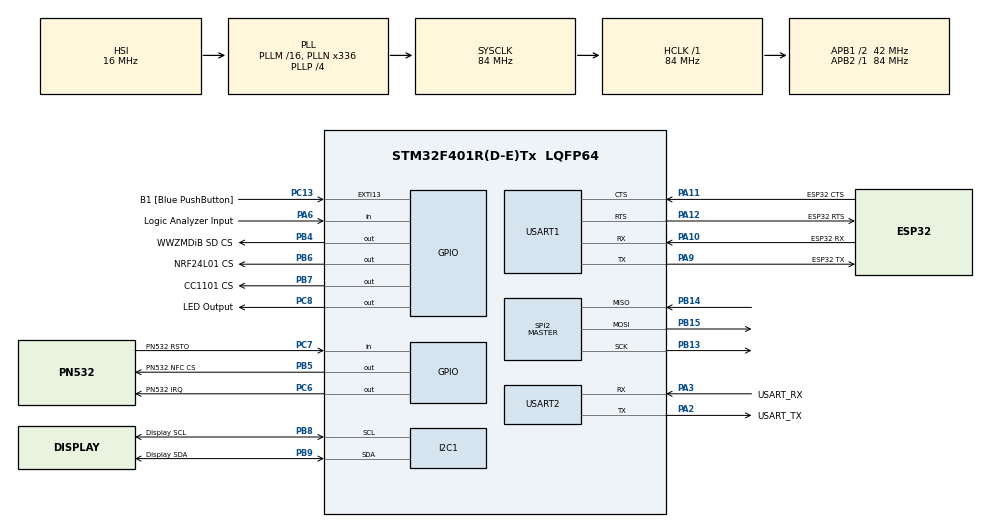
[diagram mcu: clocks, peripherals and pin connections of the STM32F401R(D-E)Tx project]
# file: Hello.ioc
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Dma.Request0=TIM3_CH4/UP
Dma.TIM3_CH4/UP.0.Direction=DMA_PERIPH_TO_MEMORY
Dma.TIM3_CH4/UP.0.FIFOMode=DMA_FIFOMODE_DISABLE
Dma.TIM3_CH4/UP.0.Instance=DMA1_Stream2
Dma.TIM3_CH4/UP.0.MemDataAlignment=DMA_MDATAALIGN_HALFWORD
Dma.TIM3_CH4/UP.0.MemInc=DMA_MINC_ENABLE
Dma.TIM3_CH4/UP.0.Mode=DMA_CIRCULAR
Dma.TIM3_CH4/UP.0.PeriphDataAlignment=DMA_PDATAALIGN_HALFWORD
Dma.TIM3_CH4/UP.0.PeriphInc=DMA_PINC_DISABLE
Dma.TIM3_CH4/UP.0.Priority=DMA_PRIORITY_HIGH
FREERTOS.Tasks01=defaultTask,24,128,StartDefaultTask,Default,NULL,Dynamic,NULL,NULL
Mcu.Family=STM32F4
Mcu.Name=STM32F401R(D-E)Tx
Mcu.Package=LQFP64
NVIC.DMA1_Stream2_IRQn=true\:5\:0\:false\:false\:true\:true\:false\:true\:true
NVIC.PriorityGroup=NVIC_PRIORITYGROUP_4
NVIC.TIM1_UP_TIM10_IRQn=true\:15\:0\:false\:false\:true\:false\:false\:true\:true
NVIC.TimeBase=TIM1_UP_TIM10_IRQn
NVIC.TimeBaseIP=TIM1
PA10.GPIO_Label=ESP32 RX
PA10.Mode=Asynchronous
PA10.Signal=USART1_RX
PA11.GPIO_Label=ESP32 CTS
PA11.Mode=CTS_RTS
PA11.Signal=USART1_CTS
PA12.GPIO_Label=ESP32 RTS
PA12.Mode=CTS_RTS
PA12.Signal=USART1_RTS
PA13.GPIO_Label=TMS
PA13.Mode=Trace_Asynchronous_SW
PA13.Signal=SYS_JTMS-SWDIO
PA14.GPIO_Label=TCK
PA14.Mode=Trace_Asynchronous_SW
PA14.Signal=SYS_JTCK-SWCLK
PA2.GPIO_Label=USART_TX
PA2.GPIO_Mode=GPIO_MODE_AF_PP
PA2.GPIO_PuPd=GPIO_NOPULL
PA2.GPIO_Speed=GPIO_SPEED_FREQ_LOW
PA2.Mode=Asynchronous
PA2.Signal=USART2_TX
PA3.GPIO_Label=USART_RX
PA3.GPIO_Mode=GPIO_MODE_AF_PP
PA3.GPIO_PuPd=GPIO_NOPULL
PA3.GPIO_Speed=GPIO_SPEED_FREQ_LOW
PA3.Mode=Asynchronous
PA3.Signal=USART2_RX
PA6.GPIO_Label=Logic Analyzer Input
PA6.Signal=GPIO_Input
PA9.GPIO_Label=ESP32 TX
PA9.Mode=Asynchronous
PA9.Signal=USART1_TX
PB10.Signal=I2C2_SCL
PB13.Mode=Full_Duplex_Master
PB13.Signal=SPI2_SCK
PB14.Mode=Full_Duplex_Master
PB14.Signal=SPI2_MISO
PB15.Mode=Full_Duplex_Master
PB15.Signal=SPI2_MOSI
PB3.GPIO_Label=SWO
PB3.Mode=Trace_Asynchronous_SW
PB3.Signal=SYS_JTDO-SWO
PB4.GPIO_Label=WWZMDiB SD CS
PB4.Signal=GPIO_Output
PB5.GPIO_Label=PN532 NFC CS
PB5.Signal=GPIO_Output
PB6.GPIO_Label=NRF24L01 CS
PB6.Signal=GPIO_Output
PB7.GPIO_Label=CC1101 CS
PB7.Signal=GPIO_Output
PB8.GPIO_Label=Display SCL
PB8.Mode=I2C
PB8.Signal=I2C1_SCL
PB9.GPIO_Label=Display SDA
PB9.Mode=I2C
PB9.Signal=I2C1_SDA
PC13-ANTI_TAMP.GPIO_Label=B1 [Blue PushButton]
PC13-ANTI_TAMP.GPIO_ModeDefaultEXTI=GPIO_MODE_IT_FALLING
PC13-ANTI_TAMP.GPIO_PuPd=GPIO_NOPULL
PC13-ANTI_TAMP.Signal=GPXTI13
PC14-OSC32_IN.Mode=LSE-External-Oscillator
PC14-OSC32_IN.Signal=RCC_OSC32_IN
PC15-OSC32_OUT.Mode=LSE-External-Oscillator
PC15-OSC32_OUT.Signal=RCC_OSC32_OUT
PC6.GPIO_Label=PN532 IRQ
PC6.Signal=GPIO_Output
PC7.GPIO_Label=PN532 RSTO
PC7.Signal=GPIO_Input
PC8.GPIO_Label=LED Output
PC8.Signal=GPIO_Output
PH0\ -\ OSC_IN.Mode=HSE-External-Clock-Source
PH0\ -\ OSC_IN.Signal=RCC_OSC_IN
PH1\ -\ OSC_OUT.Mode=HSE-External-Clock-Source
PH1\ -\ OSC_OUT.Signal=RCC_OSC_OUT
ProjectManager.HeapSize=0x200
ProjectManager.StackSize=0x400
ProjectManager.TargetToolchain=Makefile
RCC.48MHZClocksFreq_Value=48000000
RCC.AHBFreq_Value=84000000
RCC.APB1CLKDivider=RCC_HCLK_DIV2
RCC.APB1Freq_Value=42000000
RCC.APB1TimFreq_Value=84000000
RCC.APB2Freq_Value=84000000
RCC.APB2TimFreq_Value=84000000
RCC.CortexFreq_Value=84000000
RCC.HCLKFreq_Value=84000000
RCC.HSE_VALUE=8000000
RCC.HSI_VALUE=16000000
RCC.PLLN=336
RCC.PLLP=RCC_PLLP_DIV4
RCC.PLLQ=7
RCC.SYSCLKFreq_VALUE=84000000
RCC.SYSCLKSource=RCC_SYSCLKSOURCE_PLLCLK
RCC.VCOOutputFreq_Value=336000000
SPI2.Direction=SPI_DIRECTION_2LINES
SPI2.Mode=SPI_MODE_MASTER
SPI2.VirtualType=VM_MASTER
TIM3.Channel-Output\ Compare1\ No\ Output=TIM_CHANNEL_1
TIM3.TIM_MasterOutputTrigger=TIM_TRGO_UPDATE
TIM3.TIM_MasterSlaveMode=TIM_MASTERSLAVEMODE_ENABLE
USART1.VirtualMode=VM_ASYNC
USART2.VirtualMode=VM_ASYNC
VP_FREERTOS_VS_CMSIS_V2.Mode=CMSIS_V2
VP_SYS_VS_tim1.Mode=TIM1
VP_TIM3_VS_no_output1.Mode=Output Compare1 No Output
board=NUCLEO-F401RE

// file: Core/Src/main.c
/* USER CODE BEGIN Header */
/**
 ******************************************************************************
 * @file           : main.c
 * @brief          : Main program body
 ******************************************************************************
 * @attention
 *
 * Copyright (c) 2025 STMicroelectronics.
 * All rights reserved.
 *
 * This software is licensed under terms that can be found in the LICENSE file
 * in the root directory of this software component.
 * If no LICENSE file comes with this software, it is provided AS-IS.
 *
 ******************************************************************************
 */
/* USER CODE END Header */
#include "main.h"
#include "cmsis_os.h"
#include <stdarg.h>
#include <stdio.h>
#include <string.h>

// TODO: Move NFC-related functions and macros to separate nfc files
#define NFC_MAX_OUTPUT_BUFFER_SIZE \
	255 // Note: Non-data fields use 8 bytes. Data field can be 247 bytes max
#define NFC_TRANSMIT_PREAMBLE 0x00
#define NFC_TRANSMIT_START1 0x00
#define NFC_TRANSMIT_START2 0xFF
#define NFC_TRANSMIT_TO_STM 0xD5
#define NFC_TRANSMIT_TO_PN 0xD4
#define NFC_TRANSMIT_POSTAMBLE 0x00
#define UART_PRINT_BUFFER 128

I2C_HandleTypeDef hi2c1;

SPI_HandleTypeDef hspi2;

TIM_HandleTypeDef htim3;
DMA_HandleTypeDef hdma_tim3_ch4_up;

UART_HandleTypeDef huart1;
UART_HandleTypeDef huart2;

/* Definitions for defaultTask */
osThreadId_t defaultTaskHandle;
const osThreadAttr_t defaultTask_attributes = {
    .name = "defaultTask",
    .stack_size = 128 * 4,
    .priority = (osPriority_t)osPriorityNormal,
};
/* USER CODE BEGIN PV */

void SystemClock_Config(void);
static void MX_GPIO_Init(void);
static void MX_DMA_Init(void);
static void MX_USART2_UART_Init(void);
static void MX_I2C1_Init(void);
static void MX_SPI2_Init(void);
static void MX_USART1_UART_Init(void);
static void MX_TIM3_Init(void);
void StartDefaultTask(void *argument);

static void StPrint(const char *format, ...)
{
	char buffer[UART_PRINT_BUFFER];

	va_list args;                                    // Points to optional arguments on stack
	va_start(args, format);                          // args now points to the first optional argument
	vsnprintf(buffer, sizeof(buffer), format, args); // Format string w/ args
	va_end(args);                                    // Reset pointer/clean up to avoid possible stack smashing
	HAL_UART_Transmit(&huart2, (uint8_t *)buffer, strlen(buffer),
	                  HAL_MAX_DELAY);
}

int main(void)
{

	/* MCU
	 * Configuration--------------------------------------------------------*/

	/* Reset of all peripherals, Initializes the Flash interface and the
	 * Systick. */
	HAL_Init();

	/* Configure the system clock */
	SystemClock_Config();

	/* Initialize all configured peripherals */
	MX_GPIO_Init();
	MX_DMA_Init();
	MX_USART2_UART_Init();
	MX_I2C1_Init();
	MX_SPI2_Init();
	MX_USART1_UART_Init();
	MX_TIM3_Init();

	/* Init scheduler */
	osKernelInitialize();

	/* Create the thread(s) */
	/* creation of defaultTask */
	defaultTaskHandle =
	    osThreadNew(StartDefaultTask, NULL, &defaultTask_attributes);

	/* Start scheduler */
	osKernelStart();

	/* We should never get here as control is now taken by the scheduler */

	/* Infinite loop */
	while (1)
	{

	}
}

void SystemClock_Config(void)
{
	RCC_OscInitTypeDef RCC_OscInitStruct = {0};
	RCC_ClkInitTypeDef RCC_ClkInitStruct = {0};

	/** Configure the main internal regulator output voltage
	 */
	__HAL_RCC_PWR_CLK_ENABLE();
	__HAL_PWR_VOLTAGESCALING_CONFIG(PWR_REGULATOR_VOLTAGE_SCALE2);

	/** Initializes the RCC Oscillators according to the specified parameters
	 * in the RCC_OscInitTypeDef structure.
	 */
	RCC_OscInitStruct.OscillatorType = RCC_OSCILLATORTYPE_HSI;
	RCC_OscInitStruct.HSIState = RCC_HSI_ON;
	RCC_OscInitStruct.HSICalibrationValue = RCC_HSICALIBRATION_DEFAULT;
	RCC_OscInitStruct.PLL.PLLState = RCC_PLL_ON;
	RCC_OscInitStruct.PLL.PLLSource = RCC_PLLSOURCE_HSI;
	RCC_OscInitStruct.PLL.PLLM = 16;
	RCC_OscInitStruct.PLL.PLLN = 336;
	RCC_OscInitStruct.PLL.PLLP = RCC_PLLP_DIV4;
	RCC_OscInitStruct.PLL.PLLQ = 7;
	if (HAL_RCC_OscConfig(&RCC_OscInitStruct) != HAL_OK)
	{
		Error_Handler();
	}

	/** Initializes the CPU, AHB and APB buses clocks
	 */
	RCC_ClkInitStruct.ClockType = RCC_CLOCKTYPE_HCLK | RCC_CLOCKTYPE_SYSCLK |
	                              RCC_CLOCKTYPE_PCLK1 | RCC_CLOCKTYPE_PCLK2;
	RCC_ClkInitStruct.SYSCLKSource = RCC_SYSCLKSOURCE_PLLCLK;
	RCC_ClkInitStruct.AHBCLKDivider = RCC_SYSCLK_DIV1;
	RCC_ClkInitStruct.APB1CLKDivider = RCC_HCLK_DIV2;
	RCC_ClkInitStruct.APB2CLKDivider = RCC_HCLK_DIV1;

	if (HAL_RCC_ClockConfig(&RCC_ClkInitStruct, FLASH_LATENCY_2) != HAL_OK)
	{
		Error_Handler();
	}
}

static void MX_I2C1_Init(void)
{

	hi2c1.Instance = I2C1;
	hi2c1.Init.ClockSpeed = 100000;
	hi2c1.Init.DutyCycle = I2C_DUTYCYCLE_2;
	hi2c1.Init.OwnAddress1 = 0;
	hi2c1.Init.AddressingMode = I2C_ADDRESSINGMODE_7BIT;
	hi2c1.Init.DualAddressMode = I2C_DUALADDRESS_DISABLE;
	hi2c1.Init.OwnAddress2 = 0;
	hi2c1.Init.GeneralCallMode = I2C_GENERALCALL_DISABLE;
	hi2c1.Init.NoStretchMode = I2C_NOSTRETCH_DISABLE;
	if (HAL_I2C_Init(&hi2c1) != HAL_OK)
	{
		Error_Handler();
	}
}

static void MX_SPI2_Init(void)
{

	/* SPI2 parameter configuration*/
	hspi2.Instance = SPI2;
	hspi2.Init.Mode = SPI_MODE_MASTER;
	hspi2.Init.Direction = SPI_DIRECTION_2LINES;
	hspi2.Init.DataSize = SPI_DATASIZE_8BIT;
	hspi2.Init.CLKPolarity = SPI_POLARITY_LOW;
	hspi2.Init.CLKPhase = SPI_PHASE_1EDGE;
	hspi2.Init.NSS = SPI_NSS_SOFT;
	hspi2.Init.BaudRatePrescaler = SPI_BAUDRATEPRESCALER_2;
	hspi2.Init.FirstBit = SPI_FIRSTBIT_MSB;
	hspi2.Init.TIMode = SPI_TIMODE_DISABLE;
	hspi2.Init.CRCCalculation = SPI_CRCCALCULATION_DISABLE;
	hspi2.Init.CRCPolynomial = 10;
	if (HAL_SPI_Init(&hspi2) != HAL_OK)
	{
		Error_Handler();
	}
}

static void MX_TIM3_Init(void)
{

	TIM_MasterConfigTypeDef sMasterConfig = {0};
	TIM_OC_InitTypeDef sConfigOC = {0};

	htim3.Instance = TIM3;
	htim3.Init.Prescaler = 0;
	htim3.Init.CounterMode = TIM_COUNTERMODE_UP;
	htim3.Init.Period = 65535;
	htim3.Init.ClockDivision = TIM_CLOCKDIVISION_DIV1;
	htim3.Init.AutoReloadPreload = TIM_AUTORELOAD_PRELOAD_DISABLE;
	if (HAL_TIM_OC_Init(&htim3) != HAL_OK)
	{
		Error_Handler();
	}
	sMasterConfig.MasterOutputTrigger = TIM_TRGO_UPDATE;
	sMasterConfig.MasterSlaveMode = TIM_MASTERSLAVEMODE_ENABLE;
	if (HAL_TIMEx_MasterConfigSynchronization(&htim3, &sMasterConfig) != HAL_OK)
	{
		Error_Handler();
	}
	sConfigOC.OCMode = TIM_OCMODE_TIMING;
	sConfigOC.Pulse = 0;
	sConfigOC.OCPolarity = TIM_OCPOLARITY_HIGH;
	sConfigOC.OCFastMode = TIM_OCFAST_DISABLE;
	if (HAL_TIM_OC_ConfigChannel(&htim3, &sConfigOC, TIM_CHANNEL_1) != HAL_OK)
	{
		Error_Handler();
	}
}

static void MX_USART1_UART_Init(void)
{

	huart1.Instance = USART1;
	huart1.Init.BaudRate = 115200;
	huart1.Init.WordLength = UART_WORDLENGTH_8B;
	huart1.Init.StopBits = UART_STOPBITS_1;
	huart1.Init.Parity = UART_PARITY_NONE;
	huart1.Init.Mode = UART_MODE_TX_RX;
	huart1.Init.HwFlowCtl = UART_HWCONTROL_RTS_CTS;
	huart1.Init.OverSampling = UART_OVERSAMPLING_16;
	if (HAL_UART_Init(&huart1) != HAL_OK)
	{
		Error_Handler();
	}
}

static void MX_USART2_UART_Init(void)
{

	huart2.Instance = USART2;
	huart2.Init.BaudRate = 115200;
	huart2.Init.WordLength = UART_WORDLENGTH_8B;
	huart2.Init.StopBits = UART_STOPBITS_1;
	huart2.Init.Parity = UART_PARITY_NONE;
	huart2.Init.Mode = UART_MODE_TX_RX;
	huart2.Init.HwFlowCtl = UART_HWCONTROL_NONE;
	huart2.Init.OverSampling = UART_OVERSAMPLING_16;
	if (HAL_UART_Init(&huart2) != HAL_OK)
	{
		Error_Handler();
	}
}

static void MX_DMA_Init(void)
{

	/* DMA controller clock enable */
	__HAL_RCC_DMA1_CLK_ENABLE();

	/* DMA interrupt init */
	/* DMA1_Stream2_IRQn interrupt configuration */
	HAL_NVIC_SetPriority(DMA1_Stream2_IRQn, 5, 0);
	HAL_NVIC_EnableIRQ(DMA1_Stream2_IRQn);
}

static void MX_GPIO_Init(void)
{
	GPIO_InitTypeDef GPIO_InitStruct = {0};

	/* GPIO Ports Clock Enable */
	__HAL_RCC_GPIOC_CLK_ENABLE();
	__HAL_RCC_GPIOH_CLK_ENABLE();
	__HAL_RCC_GPIOA_CLK_ENABLE();
	__HAL_RCC_GPIOB_CLK_ENABLE();

	/*Configure GPIO pin Output Level */
	HAL_GPIO_WritePin(GPIOC, PN532_IRQ_Pin | LED_Output_Pin, GPIO_PIN_RESET);

	/*Configure GPIO pin Output Level */
	HAL_GPIO_WritePin(GPIOB,
	                  WWZMDiB_SD_CS_Pin | PN532_NFC_CS_Pin | NRF24L01_CS_Pin |
	                      CC1101_CS_Pin,
	                  GPIO_PIN_RESET);

	/*Configure GPIO pin : B1_Pin */
	GPIO_InitStruct.Pin = B1_Pin;
	GPIO_InitStruct.Mode = GPIO_MODE_IT_FALLING;
	GPIO_InitStruct.Pull = GPIO_NOPULL;
	HAL_GPIO_Init(B1_GPIO_Port, &GPIO_InitStruct);

	/*Configure GPIO pin : Logic_Analyzer_Input_Pin */
	GPIO_InitStruct.Pin = Logic_Analyzer_Input_Pin;
	GPIO_InitStruct.Mode = GPIO_MODE_INPUT;
	GPIO_InitStruct.Pull = GPIO_NOPULL;
	HAL_GPIO_Init(Logic_Analyzer_Input_GPIO_Port, &GPIO_InitStruct);

	/*Configure GPIO pin : PB10 */
	GPIO_InitStruct.Pin = GPIO_PIN_10;
	GPIO_InitStruct.Mode = GPIO_MODE_AF_OD;
	GPIO_InitStruct.Pull = GPIO_NOPULL;
	GPIO_InitStruct.Speed = GPIO_SPEED_FREQ_VERY_HIGH;
	GPIO_InitStruct.Alternate = GPIO_AF4_I2C2;
	HAL_GPIO_Init(GPIOB, &GPIO_InitStruct);

	/*Configure GPIO pins : PN532_IRQ_Pin LED_Output_Pin */
	GPIO_InitStruct.Pin = PN532_IRQ_Pin | LED_Output_Pin;
	GPIO_InitStruct.Mode = GPIO_MODE_OUTPUT_PP;
	GPIO_InitStruct.Pull = GPIO_NOPULL;
	GPIO_InitStruct.Speed = GPIO_SPEED_FREQ_LOW;
	HAL_GPIO_Init(GPIOC, &GPIO_InitStruct);

	/*Configure GPIO pin : PN532_RSTO_Pin */
	GPIO_InitStruct.Pin = PN532_RSTO_Pin;
	GPIO_InitStruct.Mode = GPIO_MODE_INPUT;
	GPIO_InitStruct.Pull = GPIO_NOPULL;
	HAL_GPIO_Init(PN532_RSTO_GPIO_Port, &GPIO_InitStruct);

	/*Configure GPIO pins : WWZMDiB_SD_CS_Pin PN532_NFC_CS_Pin NRF24L01_CS_Pin
	 * CC1101_CS_Pin */
	GPIO_InitStruct.Pin =
	    WWZMDiB_SD_CS_Pin | PN532_NFC_CS_Pin | NRF24L01_CS_Pin | CC1101_CS_Pin;
	GPIO_InitStruct.Mode = GPIO_MODE_OUTPUT_PP;
	GPIO_InitStruct.Pull = GPIO_NOPULL;
	GPIO_InitStruct.Speed = GPIO_SPEED_FREQ_LOW;
	HAL_GPIO_Init(GPIOB, &GPIO_InitStruct);

}

/**
 * @brief  Resets PN532 NFC module via RSTO line
 * @param  argument: Not used
 * @retval None
 */
static void NfcReset(void)
{
	HAL_GPIO_WritePin(PN532_RSTO_GPIO_Port, PN532_RSTO_Pin, GPIO_PIN_RESET);
	osDelay(2);
	HAL_GPIO_WritePin(PN532_RSTO_GPIO_Port, PN532_RSTO_Pin, GPIO_PIN_SET);
	osDelay(100);
}

static HAL_StatusTypeDef NfcSendCommand(uint8_t *command, uint16_t commandSize)
{
	HAL_StatusTypeDef retValue;

	HAL_GPIO_WritePin(GPIOB, PN532_NFC_CS_Pin, GPIO_PIN_RESET);
	retValue = HAL_SPI_Transmit(&hspi2, command, commandSize, HAL_MAX_DELAY);
	HAL_GPIO_WritePin(GPIOB, PN532_NFC_CS_Pin, GPIO_PIN_SET);
	return retValue;
}

static HAL_StatusTypeDef NfcReceiveCommand(uint8_t *response,
                                           uint16_t responseSize)
{
	HAL_StatusTypeDef retValue;

	osDelay(10);
	HAL_GPIO_WritePin(GPIOB, PN532_NFC_CS_Pin, GPIO_PIN_RESET);
	retValue = HAL_SPI_Receive(&hspi2, response, responseSize, HAL_MAX_DELAY);
	HAL_GPIO_WritePin(GPIOB, PN532_NFC_CS_Pin, GPIO_PIN_SET);

	// Check for a valid response
	if (response[0] == NFC_TRANSMIT_TO_STM && response[1] == 0x03)
	{
		StPrint("IC version: %d\r\n", response[2]);
		StPrint("Firmware version: %d\r\n", response[3]);
		StPrint("Revision version: %d\r\n", response[4]);
		StPrint("Support version: %d\r\n", response[5]);
	}
	else
	{
		StPrint("NfcReceiveCommand() Invalid response\r\n");
	}

	return retValue;
}

static HAL_StatusTypeDef NfcGetFirmwareVersion(void)
{
	uint8_t dataSize = 2;
	uint8_t response = 12;
	HAL_StatusTypeDef retValue = 0;
	uint8_t command[] = {
	    NFC_TRANSMIT_PREAMBLE,  // [PREAMBLE]
	    NFC_TRANSMIT_START1,    // [START CODE]
	    NFC_TRANSMIT_START2,    // [START CODE]
	    dataSize,               // [LEN]
	    (256 - dataSize),       // [LCS] Checksum (256 - length)
	    NFC_TRANSMIT_TO_PN,     // [DATA] (TFI)
	    0x02,                   // [DATA] (PD0)
	    0x2A,                   // [DCS] Checksum (TFI + PD0 + ... PDn + DCS == 0) (0xD6 + 0x2A)
	    NFC_TRANSMIT_POSTAMBLE, // [POSTAMBLE] Always 0x00
	};

	retValue = NfcSendCommand(command, sizeof(command));
	if (retValue != HAL_OK)
	{
		StPrint("NfcSendCommand() error code: %d\r\n", retValue);
		return retValue;
	}

	retValue = NfcReceiveCommand(command, sizeof(command));
	if (retValue != HAL_OK)
	{
		StPrint("NfcReceiveCommand() error code: %d\r\n", retValue);
		return retValue;
	}

	return retValue;
}

void StartDefaultTask(void *argument)
{
	uint8_t loop = 0;
	/* Infinite loop */
	for (;;)
	{
		StPrint("Hello World!: %d\r\n", loop);
		loop++;
		osDelay(1000);
	}
}

void HAL_TIM_PeriodElapsedCallback(TIM_HandleTypeDef *htim)
{
	if (htim->Instance == TIM1)
	{
		HAL_IncTick();
	}
}

void Error_Handler(void)
{
	/* USER CODE BEGIN Error_Handler_Debug */
	/* User can add his own implementation to report the HAL error return state
	 */
	__disable_irq();
	while (1)
	{
	}
	/* USER CODE END Error_Handler_Debug */
}

#ifdef USE_FULL_ASSERT
/**
 * @brief  Reports the name of the source file and the source line number
 *         where the assert_param error has occurred.
 * @param  file: pointer to the source file name
 * @param  line: assert_param error line source number
 * @retval None
 */
void assert_failed(uint8_t *file, uint32_t line)
{
	/* USER CODE BEGIN 6 */
	/* User can add his own implementation to report the file name and line
	 * number, */
	/* USER CODE END 6 */
}
#endif /* USE_FULL_ASSERT */
